# PIC32CK1012GC00048 device description
Architecture: CORTEX-M33; Family: PIC32CK; Series: PIC32CKGC00
Registers are 32-bit, read-write, reset 0x0 unless marked. A register's access mark holds for its fields unless they carry their own. Offsets are from the block's base; [hi:lo] are bit positions; 'fields as' and 'values as' point back to an identical list.

## SUPC — Supply Controller
Instances: SUPC 0x44008000
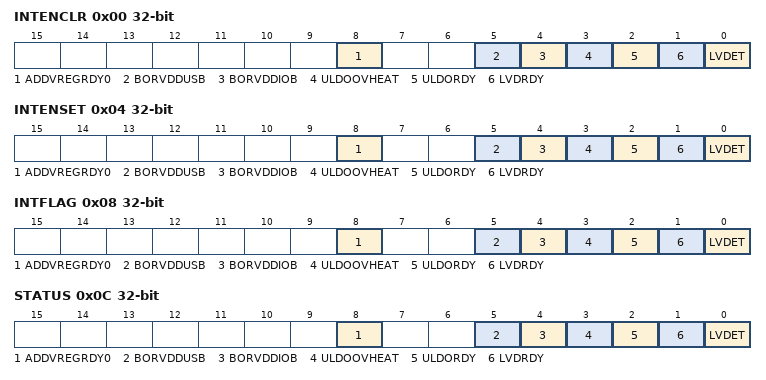
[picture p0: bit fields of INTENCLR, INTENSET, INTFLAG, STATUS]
0x00 INTENCLR (atomic clear) — Interrupt Enable Clear
  [8] ADDVREGRDY0 — Additional Regulator ready 0 Interrupt Enable
  [5] BORVDDUSB — BORVDDUSB Interrupt Enable
  [4] BORVDDIOB — BORVDDIOB Interrupt Enable
  [3] ULDOOVHEAT — User LDO Regulator OverHeat Interrupt Enable
  [2] ULDORDY — User LDO Regulator Ready Interrupt Enable
  [1] LVDRDY — Low Voltage Detector Ready Interrupt Enable
  [0] LVDET — Low Voltage Detector Interrupt Enable
0x04 INTENSET (atomic set) — Interrupt Enable Set
  fields as INTENCLR
0x08 INTFLAG (atomic clear) — Interrupt Flag Status and Clear
  [8] ADDVREGRDY0 — Additional Regulator ready 0 Interrupt. Set to one if additionnal regulator is ready meaning that output voltage is correct.
  [5] BORVDDUSB — BORVDDUSB Interrupt. Set to one if VDDUSB issue is detected.
  [4] BORVDDIOB — BORVDDIOB Interrupt. Set to one if VDDIOB issue is detected.
  [3] ULDOOVHEAT — User LDO Regulator OverHeat Interrupt. Is set to one if overheat condition is detected.
  [2] ULDORDY — User LDO Regulator Ready Interrupt. Set to one if ULDO is ready meaning that output voltage is correct.
  [1] LVDRDY — Low Voltage Detector Ready Interrupt. Set to one if LVD is ready to operate.
  [0] LVDET — Low Voltage Detector Interrupt. Set to one if VDDIO crosses the treshold voltage in the good direction according to LVD.DIR.
0x0C STATUS ro — Flag status
  [8] ADDVREGRDY0 — Additional Regulator ready 0 Status. One if voltage is OK. It corresponds to vreg_ready_mv signal of additional regulator.
  [5] BORVDDUSB — BORVDDUSB Status. One if VDDUSB is OK. It corresponds to bor_vddusb_n_mv signal of SMOR.
  [4] BORVDDIOB — BORVDDIOB Status. One if VDDIOB is OK. It corresponds to bor_vddiob_mv signal of SMOR.
  [3] ULDOOVHEAT — User LDO Regulator OverHeat Status. It corresponds to vreg_overheat_event_mv signal from ULDO.
  [2] ULDORDY — User LDO regulator Status. It corresponds to vreg_ready_mv signal from ULDO.
  [1] LVDRDY — Low Voltage Detector Ready Status
  [0] LVDET — Low Voltage Detector Status.
0x10 SYNCBUSY ro — Synchronisation Busy
  [0] BOR — BOR Synchronization Busy
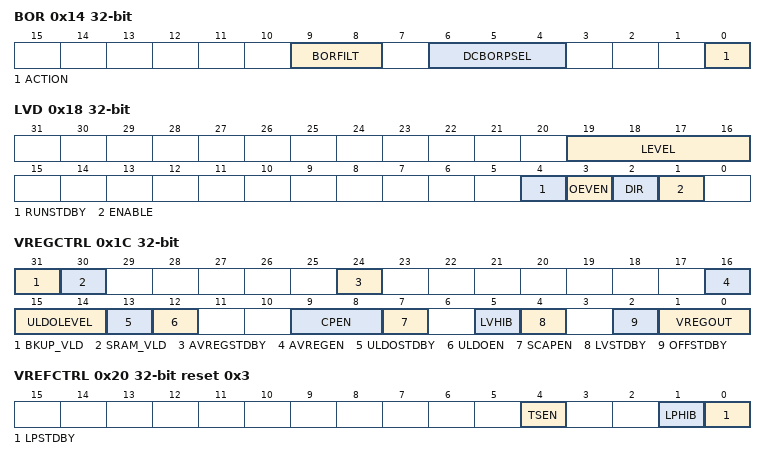
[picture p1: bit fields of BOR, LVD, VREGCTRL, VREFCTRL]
0x14 BOR — BOR Control
  [9:8] BORFILT — BOR filtering
    0=NOFILT (No digital filtering); 1=FILT32US (32us filtering); 2=FILT125US (125us filtering); 3=FILT250US (250us filtering)
  [6:4] DCBORPSEL — Duty Cycle BOR Prescaler Select
    0=NODIV (Not Divided); 1=DIV2 (Divide clock by 2); 2=DIV4 (Divide clock by 4); 3=DIV8 (Divide clock by 8); 4=DIV16 (Divide clock by 16); 5=DIV32 (Divide clock by 32); 6=DIV64 (Divide clock by 64); 7=DIV128 (Divide clock by 128)
  [0] ACTION — Action when Threshold Crossed
    0=RESET (The BOR generates a reset); 1=BBKUP (The BOR puts the device in battery backup sleep mode)
0x18 LVD — LVD Control
  [19:16] LEVEL — Threshold Level. See "pwr_smor_[nn]_v1 DOS" - level section to get details.
  [4] RUNSTDBY — Run during Standby
  [3] OEVEN — Output Event Enable
  [2] DIR — Direction
    0=Rising detection; 1=Falling detection
  [1] ENABLE
0x1C VREGCTRL — VREG Control
  [31] BKUP_VLD — Backup Domain Valid Status Bit
  [30] SRAM_VLD — SRAM VALID Status Bit
  [24] AVREGSTDBY — Additional Voltage Regulator Configuration
    0=OFFINSTDBY (Regulator is OFF while in sleep mode equal or deeper than standby mode. It is OFF in hibernate and backup mode as well.); 1=ONINSTDBY (Regulator is ON in Standby mode if AVREGEN bit is set. is OFF from Hibernate mode. It is OFF in backup mode as well.)
  [16] AVREGEN — Additional Voltage Regulator Enable
  [15:14] ULDOLEVEL — User LDO Voltage Level Selection
    0=1p2v (Vout = 1.2v); 1=1p5v (Vout = 1.5v); 2=1p8v (Vout = 1.8v); 3=2p5v (Vout = 2.5v)
  [13] ULDOSTDBY — User LDO Voltage Regulator Configuration
    0=OFFINSTDBY (Regulator is OFF while in sleep mode equal or deeper than standby mode. It is OFF in hibernate and backup mode as well.); 1=ONINSTDBY (Regulator is ON in Standby mode. is OFF from Hibernate mode. It is OFF in backup mode as well.)
  [12] ULDOEN — User LDO Voltage Regulator Enable
  [9:8] CPEN — Charge Pump Enable and Auto-enable.
  [7] SCAPEN — Super Capacitor Charging Enable
  [5] LVHIB — Low Voltage Hibernate Enable
    0=1p2v (In Hibernate mode, VDDCORE_BU and VDDCORE_RAM are set to 1.2v.); 1=0p8v (In Hibernate mode, VDDCORE_BU and VDDCORE_RAM are set to 0.8v)
  [4] LVSTDBY — Low Voltage Standby Enable
    0=1p2v (In standby mode, VDDCORE_BU, VDDCORE_RAM, VDDCORE_SW and optionnaly VDDCOREUSB/PLL are set to 1.2v.); 1=0p8v (In standby mode, VDDCORE_BU, VDDCORE_RAM, VDDCORE_SW and optionnaly VDDCOREUSB/PLL are set to 0.8v.)
  [2] OFFSTDBY — Off in Standby Control for VREGSW[N-1]. Useful for Riverside only.
    0=OFF (In standby mode, VREGSW1,2,3 are OFF); 1=ON (In standby mode, VREGSW1,2,3 are ON)
  [1:0] VREGOUT — VREG Output Control in RUN mode only. Enable by production fuse by CALSUPC.VREGOUTEN
    0=1p2v (In Active mode, VDDCORE_RAM, VDDCORE_BU, VDDCORE_SW and optionnaly VDDCORE_PLL USB are set to 1.2v.); 1=1p0v (In Active mode, VDDCORE_RAM, VDDCORE_BU, VDDCORE_SW and optionnaly VDDCORE_PLL USB are set to 1.0v.); 2=0p8v (In Active mode, VDDCORE_RAM, VDDCORE_BU, VDDCORE_SW and optionnaly VDDCORE_PLL USB are set to 0.8v.)
0x20 VREFCTRL reset 0x3 — VREF Control
  [4] TSEN — Temperature Sensor Output Enable
  [1] LPHIB — Bandgap and Regulators Low Power Hibernate Enable
    0=FullPower (In hibernate mode, bandgap is set to nominal power mode. As a consequence, enabled regulator(s) are set to nominal power mode.); 1=LowPower (In hibernate mode, bandgap is set to low power mode. As a consequence, enabled regulator(s) are set to low power mode.)
  [0] LPSTDBY — Bandgap and Regulators Low Power Standby Enable
    0=FullPower (In standby mode, bandgap and enabled regulator(s) are set to nominal power mode.); 1=LowPower (In standby mode, bandgap and enabled regulator(s) are set to low power mode.)
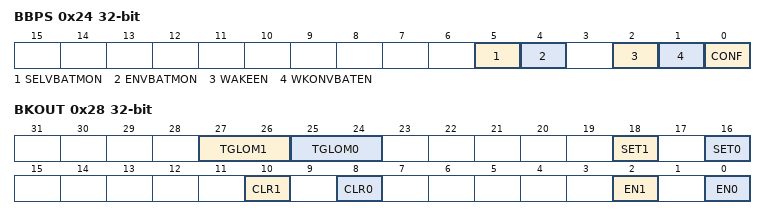
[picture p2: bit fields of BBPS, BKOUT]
0x24 BBPS — Battery Backup Power Switch. This register is implemented only if SUPC_VBAT_IMPLEMENTED==1
  [5] SELVBATMON — Select VBATMON supply voltage. 0 for VDDA, and 1 for VDDBAT.
  [4] ENVBATMON — Enables battery monitor
  [2] WAKEEN — Wake Enable
    0=DIS (When exiting battery backup mode, the device goes to backup mode.); 1=EN (When exiting battery backup mode, the device is waken-up.)
  [1] WKONVBATEN — Wake on VBAT Enable, from Backup mode
  [0] CONF — Battery Backup Power Switch Configuration
    0=BOR (The power switch is automatically handled by the BOR); 1=VBAT (In Backup mode, the power-switch is forced to VBAT.)
0x28 BKOUT — Backup Output Control
  [27:26] TGLOM1 — Toggle Output Mode
    0=DISABLE (The output does not toggle.); 1=RTCTGL (The output toggles on RTC event.); 2=BKUPTGL (The output is set when the device enters backup mode or battery backup mode. The output should then be cleared by software.)
  [25:24] TGLOM0 — Toggle Output Mode
    values as TGLOM1
  [18] SET1 — Set Output
  [16] SET0 — Set Output
  [10] CLR1 — Clear Output
  [8] CLR0 — Clear Output
  [2] EN1 — Enable Output
  [0] EN0 — Enable Output
0x2C BKIN ro — Backup Input Control
  [1:0] BKIN — Backup Input Value
